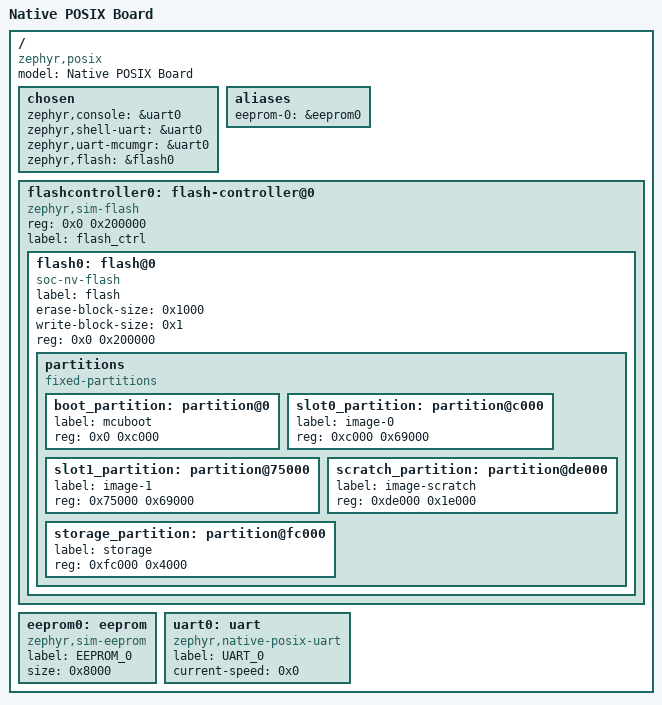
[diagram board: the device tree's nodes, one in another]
/dts-v1/;

/ {
	#address-cells = < 0x1 >;
	#size-cells = < 0x1 >;
	model = "Native POSIX Board";
	compatible = "zephyr,posix";
	chosen {
		zephyr,console = &uart0;
		zephyr,shell-uart = &uart0;
		zephyr,uart-mcumgr = &uart0;
		zephyr,flash = &flash0;
	};
	aliases {
		eeprom-0 = &eeprom0;
	};
	flashcontroller0: flash-controller@0 {
		compatible = "zephyr,sim-flash";
		reg = < 0x0 0x200000 >;
		#address-cells = < 0x1 >;
		#size-cells = < 0x1 >;
		label = "flash_ctrl";
		flash0: flash@0 {
			status = "okay";
			compatible = "soc-nv-flash";
			label = "flash";
			erase-block-size = < 0x1000 >;
			write-block-size = < 0x1 >;
			reg = < 0x0 0x200000 >;
			partitions {
				compatible = "fixed-partitions";
				#address-cells = < 0x1 >;
				#size-cells = < 0x1 >;
				boot_partition: partition@0 {
					label = "mcuboot";
					reg = < 0x0 0xc000 >;
				};
				slot0_partition: partition@c000 {
					label = "image-0";
					reg = < 0xc000 0x69000 >;
				};
				slot1_partition: partition@75000 {
					label = "image-1";
					reg = < 0x75000 0x69000 >;
				};
				scratch_partition: partition@de000 {
					label = "image-scratch";
					reg = < 0xde000 0x1e000 >;
				};
				storage_partition: partition@fc000 {
					label = "storage";
					reg = < 0xfc000 0x4000 >;
				};
			};
		};
	};
	eeprom0: eeprom {
		status = "okay";
		compatible = "zephyr,sim-eeprom";
		label = "EEPROM_0";
		size = < 0x8000 >;
	};
	uart0: uart {
		status = "okay";
		compatible = "zephyr,native-posix-uart";
		label = "UART_0";
		current-speed = < 0x0 >;
	};
};
